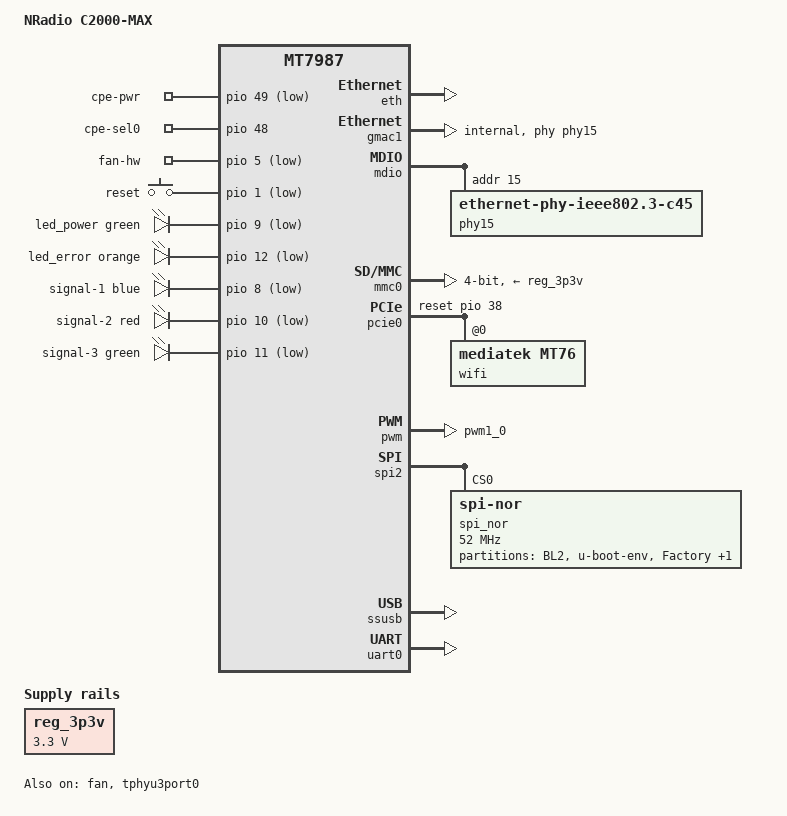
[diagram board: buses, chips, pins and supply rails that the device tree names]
// SPDX-License-Identifier: GPL-2.0-or-later OR MIT

/dts-v1/;

#include "mt7987b.dtsi"

#include <dt-bindings/input/input.h>
#include <dt-bindings/leds/common.h>

/ {
	model = "NRadio C2000-MAX";
	compatible = "nradio,c2000-max",
		     "mediatek,mt7987b",
		     "mediatek,mt7987";

	aliases {
		label-mac-device = &gmac1;
		led-boot = &led_power;
		led-failsafe = &led_error;
		led-running = &led_power;
		led-upgrade = &led_power;
		serial0 = &uart0;
	};

	chosen {
		bootargs = "console=ttyS0,115200n1 earlycon=uart8250,mmio32,0x11000000 \
		pci=pcie_bus_perf root=PARTLABEL=rootfs rootwait rootfstype=squashfs,f2fs";
		stdout-path = "serial0:115200n1";
	};

	gpio-export {
		compatible = "gpio-export";
		#size-cells = <0>;

		cpe-pwr {
			gpio-export,name = "cpe-pwr";
			gpio-export,output = <0>;
			gpios = <&pio 49 GPIO_ACTIVE_LOW>;
		};

		cpe-sel0 {
			gpio-export,name = "cpe-sel0";
			gpio-export,output = <1>;
			gpios = <&pio 48 GPIO_ACTIVE_HIGH>;
		};

		fan-hw {
			gpio-export,name = "fan-hw";
			gpio-export,output = <0>;
			gpios = <&pio 5 GPIO_ACTIVE_LOW>;
		};
	};

	gpio-keys {
		compatible = "gpio-keys";

		reset {
			label = "reset";
			linux,code = <KEY_RESTART>;
			gpios = <&pio 1 GPIO_ACTIVE_LOW>;
			debounce-interval = <10>;
		};
	};

gpio-leds {
    compatible = "gpio-leds";

    led_power: power {
        color = <LED_COLOR_ID_GREEN>;
        function = LED_FUNCTION_POWER;
        gpios = <&pio 9 GPIO_ACTIVE_LOW>;
    };

    led_error: error {
        color = <LED_COLOR_ID_ORANGE>;
        function = LED_FUNCTION_STATUS;
        gpios = <&pio 12 GPIO_ACTIVE_LOW>;
    };

    signal-1 {
        color = <LED_COLOR_ID_BLUE>;
        function = "signal";
        gpios = <&pio 8 GPIO_ACTIVE_LOW>;
    };

    signal-2 {
        color = <LED_COLOR_ID_RED>;
        function = "signal";
        gpios = <&pio 10 GPIO_ACTIVE_LOW>;
    };

    signal-3 {
        color = <LED_COLOR_ID_GREEN>;
        function = "signal";
        gpios = <&pio 11 GPIO_ACTIVE_LOW>;
    };
};

	reg_3p3v: regulator-3p3v {
		compatible = "regulator-fixed";
		regulator-name = "fixed-3.3V";
		regulator-min-microvolt = <3300000>;
		regulator-max-microvolt = <3300000>;
		regulator-boot-on;
		regulator-always-on;
	};
};

&eth {
	status = "okay";
};

&fan {
	pwms = <&pwm 1 50000 0>;
	status = "okay";
};

&gmac1 {
	phy-mode = "internal";
	phy-handle = <&phy15>;
	nvmem-cells = <&macaddr_bdinfo 0>;
	nvmem-cell-names = "mac-address";
	status = "okay";
};

&mdio {
	phy15: phy@15 {
		compatible = "ethernet-phy-ieee802.3-c45";
		reg = <15>;
		pinctrl-names = "i2p5gbe-led";
		pinctrl-0 = <&i2p5gbe_led0_pins>;
	};
};

&mmc0 {
	#address-cells = <1>;
	#size-cells = <0>;
	pinctrl-names = "default", "state_uhs";
	pinctrl-0 = <&sd_pins_default>;
	pinctrl-1 = <&sd_pins_uhs>;
	bus-width = <4>;
	max-frequency = <48000000>;
	cap-sd-highspeed;
	vmmc-supply = <&reg_3p3v>;
	vqmmc-supply = <&reg_3p3v>;
	no-mmc;
	no-sdio;
	status = "okay";
};

&pcie0 {
	pinctrl-names = "default";
	pinctrl-0 = <&pcie0_pins>;
	reset-gpios = <&pio 38 GPIO_ACTIVE_HIGH>;
	status = "okay";

	pcie@0,0 {
		reg = <0x0000 0 0 0 0>;

		wifi@0,0 {
			compatible = "mediatek,mt76";
			reg = <0x0000 0 0 0 0>;
			#address-cells = <1>;
			#size-cells = <0>;

			device_type = "pci";

			ieee80211-freq-limit = <2400000 2500000>,
					       <5170000 5835000>;

			nvmem-cells = <&eeprom_factory_0>;
			nvmem-cell-names = "eeprom";

			band@0 {
				reg = <0>;
				nvmem-cells = <&macaddr_bdinfo 1>;
				nvmem-cell-names = "mac-address";
			};

			band@1 {
				reg = <1>;
				nvmem-cells = <&macaddr_bdinfo 2>;
				nvmem-cell-names = "mac-address";
			};
		};
	};
};

&pio {
	pwm1_pins: pwm1-pins {
		mux {
			function = "pwm";
			groups = "pwm1_0";
		};
	};
};

&pwm {
	pinctrl-names = "default";
	pinctrl-0 = <&pwm1_pins>;
	status = "okay";
};

&spi2 {
	pinctrl-names = "default";
	pinctrl-0 = <&spi2_flash_pins>;
	status = "okay";

	spi_nor: flash@0 {
		compatible = "jedec,spi-nor";
		reg = <0>;
		spi-max-frequency = <52000000>;
		spi-tx-bus-width = <4>;
		spi-rx-bus-width = <4>;

		partitions {
			compatible = "fixed-partitions";
			#address-cells = <1>;
			#size-cells = <1>;

			partition@0 {
				label = "BL2";
				reg = <0x00000 0x40000>;
				read-only;
			};

			partition@40000 {
				label = "u-boot-env";
				reg = <0x40000 0x10000>;
				compatible = "u-boot,env";
			};

			partition@50000 {
				label = "Factory";
				reg = <0x50000 0x100000>;
				read-only;

				nvmem-layout {
					compatible = "fixed-layout";
					#address-cells = <1>;
					#size-cells = <1>;

					eeprom_factory_0: eeprom@0 {
						reg = <0x0 0x1e00>;
					};
				};
			};

			partition@150000 {
				label = "bdinfo";
				reg = <0x150000 0x80000>;
				read-only;

				nvmem-layout {
						compatible = "fixed-layout";
						#address-cells = <1>;
						#size-cells = <1>;

						macaddr_bdinfo: macaddr@9 {
								compatible = "mac-base";
								reg = <0x9 0x6>;
								#nvmem-cell-cells = <1>;
						};
				};
			};
		};
	};
};

&ssusb {
	status = "okay";

	vusb33-supply = <&reg_3p3v>;
};

&tphyu3port0 {
	status = "okay";
};

&uart0 {
	pinctrl-names = "default";
	pinctrl-0 = <&uart0_pins>;
	status = "okay";
};
